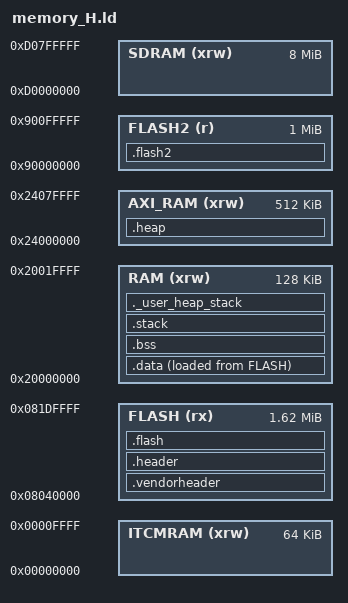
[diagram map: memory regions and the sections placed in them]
/*
******************************************************************************
**

**  File        : LinkerScript.ld
**
**  Author		: Auto-generated by Ac6 System Workbench
**
**  Abstract    : Linker script for STM32H7 series
**                1024Kbytes FLASH and 192Kbytes RAM
**
**                Set heap size, stack size and stack location according
**                to application requirements.
**
**                Set memory bank area and size if external memory is used.
**
**  Target      : STMicroelectronics STM32
**
**  Distribution: The file is distributed �as is,� without any warranty
**                of any kind.
**
*****************************************************************************
** @attention
**
** <h2><center>&copy; COPYRIGHT(c) 2014 Ac6</center></h2>
**
** Redistribution and use in source and binary forms, with or without modification,
** are permitted provided that the following conditions are met:
**   1. Redistributions of source code must retain the above copyright notice,
**      this list of conditions and the following disclaimer.
**   2. Redistributions in binary form must reproduce the above copyright notice,
**      this list of conditions and the following disclaimer in the documentation
**      and/or other materials provided with the distribution.
**   3. Neither the name of Ac6 nor the names of its contributors
**      may be used to endorse or promote products derived from this software
**      without specific prior written permission.
**
** THIS SOFTWARE IS PROVIDED BY THE COPYRIGHT HOLDERS AND CONTRIBUTORS "AS IS"
** AND ANY EXPRESS OR IMPLIED WARRANTIES, INCLUDING, BUT NOT LIMITED TO, THE
** IMPLIED WARRANTIES OF MERCHANTABILITY AND FITNESS FOR A PARTICULAR PURPOSE ARE
** DISCLAIMED. IN NO EVENT SHALL THE COPYRIGHT HOLDER OR CONTRIBUTORS BE LIABLE
** FOR ANY DIRECT, INDIRECT, INCIDENTAL, SPECIAL, EXEMPLARY, OR CONSEQUENTIAL
** DAMAGES (INCLUDING, BUT NOT LIMITED TO, PROCUREMENT OF SUBSTITUTE GOODS OR
** SERVICES; LOSS OF USE, DATA, OR PROFITS; OR BUSINESS INTERRUPTION) HOWEVER
** CAUSED AND ON ANY THEORY OF LIABILITY, WHETHER IN CONTRACT, STRICT LIABILITY,
** OR TORT (INCLUDING NEGLIGENCE OR OTHERWISE) ARISING IN ANY WAY OUT OF THE USE
** OF THIS SOFTWARE, EVEN IF ADVISED OF THE POSSIBILITY OF SUCH DAMAGE.
**
*****************************************************************************
*/

/* Entry Point */
ENTRY(Reset_Handler)

/* Highest address of the user mode stack */
_estack = 0x20020000;    /* end of RAM */
/* Generate a link error if heap and stack don't fit into RAM */
_Min_Heap_Size = 0x9400;      /* required amount of heap  */
_Min_Stack_Size = 0x1000; /* required amount of stack */

/* Specify the memory areas */
MEMORY
{
  FLASH (rx)      : ORIGIN = 0x08040000, LENGTH = 1664K
  FLASH2 (r)      : ORIGIN = 0x90000000, LENGTH = 1024K
  RAM (xrw)      : ORIGIN = 0x20000000, LENGTH = 128K
  AXI_RAM (xrw)      : ORIGIN = 0x24000000, LENGTH = 512K
  ITCMRAM (xrw)      : ORIGIN = 0x00000000, LENGTH = 64K
  SDRAM (xrw)      : ORIGIN = 0xD0000000, LENGTH = 8192K
}

/* used by the startup code to wipe memory */
sram_start = ORIGIN(RAM);
sram_end = ORIGIN(RAM) + LENGTH(RAM);
_ram_start = sram_start;
_ram_end = sram_end;

_codelen = LENGTH(FLASH) - SIZEOF(.vendorheader) - SIZEOF(.header) + SIZEOF(.flash2);
_flash_start = ORIGIN(FLASH);
_flash_end = ORIGIN(FLASH) + LENGTH(FLASH);
_heap_start = ADDR(.heap);
_heap_end = ADDR(.heap) + SIZEOF(.heap);

/* Define output sections */
SECTIONS
{
  .vendorheader : ALIGN(4) {
    KEEP(*(.vendorheader))
  } >FLASH AT>FLASH

  .header : ALIGN(4) {
    KEEP(*(.header));
  } >FLASH AT>FLASH

  .flash2 : ALIGN(512) {
    build/firmware/frozen_mpy.o(.rodata*);
    build/firmware/vendor/secp256k1-zkp/src/secp256k1.o(.rodata*);
    . = ALIGN(512);
  } >FLASH2 AT>FLASH2

  .flash : ALIGN(512) {
    KEEP(*(.isr_vector));
    . = ALIGN(4);
    *(.text*);
    . = ALIGN(4);
    *(.rodata*);
    . = ALIGN(4);
    KEEP(*(.bootloader));
    *(.bootloader*);
    . = ALIGN(512);
  } >FLASH AT>FLASH

  /* used by the startup to initialize data */
  _sidata = LOADADDR(.data);

  /* Initialized data sections goes into RAM, load LMA copy after code */
  .data : 
  {
    . = ALIGN(4);
    _sdata = .;        /* create a global symbol at data start */
    *(.data)           /* .data sections */
    *(.data*)          /* .data* sections */

    . = ALIGN(512);
    _edata = .;        /* define a global symbol at data end */
  } >RAM AT> FLASH
  
  /* Uninitialized data section */
  . = ALIGN(4);
  .bss :
  {
    /* This is used by the startup in order to initialize the .bss secion */
    _sbss = .;         /* define a global symbol at bss start */
    __bss_start__ = _sbss;
    *(.bss)
    *(.bss*)
    *(COMMON)

    . = ALIGN(4);
    _ebss = .;         /* define a global symbol at bss end */
    __bss_end__ = _ebss;
  } >RAM

  .stack : ALIGN(8) {
    . = 4K; /* this acts as a build time assertion that at least this much memory is available for stack use */
  } >RAM

  /* User_heap_stack section, used to check that there is enough RAM left */
  ._user_heap_stack :
  {
    . = ALIGN(8);
    PROVIDE ( end = . );
    PROVIDE ( _end = . );
    . = ALIGN(8);
  } >RAM

   .heap : ALIGN(4) {
    . = 512K; /* this acts as a build time assertion that at least this much memory is available for heap use */
    /* . = ABSOLUTE(sram_end - 16K);  this explicitly sets the end of the heap effectively giving the stack at most 16K */
  } >AXI_RAM

}


